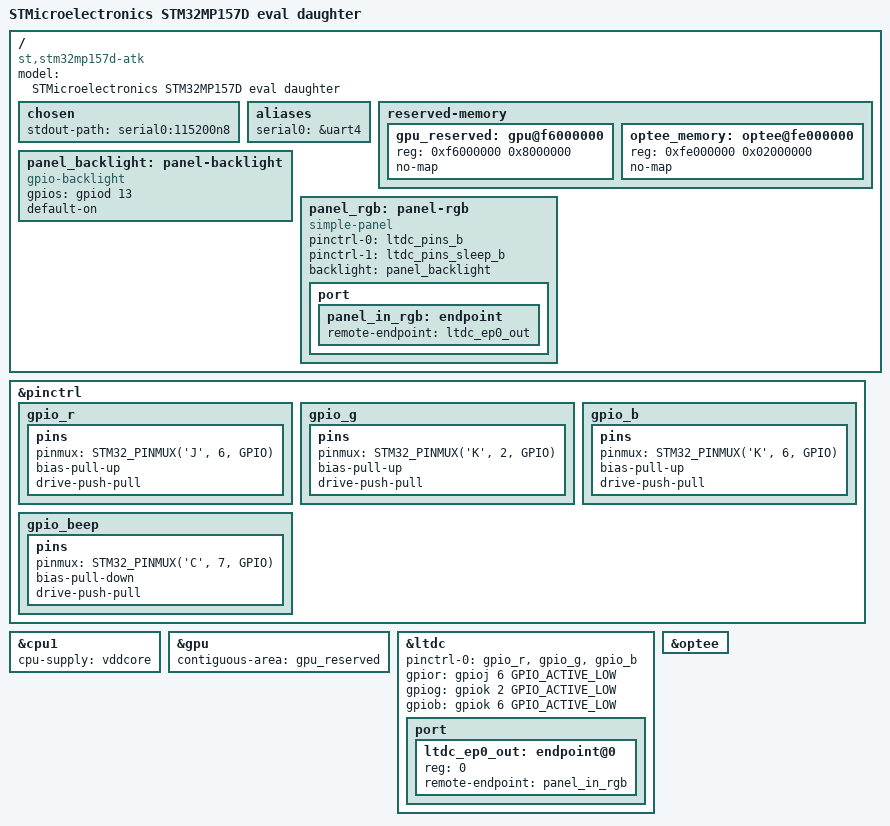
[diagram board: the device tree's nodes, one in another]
// SPDX-License-Identifier: (GPL-2.0+ OR BSD-3-Clause)
/*
 * Copyright (C) STMicroelectronics 2019 - All Rights Reserved
 * Author: Alexandre Torgue <alexandre.torgue@st.com> for STMicroelectronics.
 */
/dts-v1/;

#include "stm32mp157.dtsi"
#include "stm32mp15xd.dtsi"
#include "stm32mp15-pinctrl.dtsi"
#include "stm32mp15xxaa-pinctrl.dtsi"
#include "stm32mp157-m4-srm.dtsi"
#include "stm32mp157-m4-srm-pinctrl.dtsi"
#include "stm32mp157d-atk.dtsi"

/ {
	model = "STMicroelectronics STM32MP157D eval daughter";
	compatible = "st,stm32mp157d-atk", "st,stm32mp157";

	chosen {
		stdout-path = "serial0:115200n8";
	};

	aliases {
		serial0 = &uart4;
	};

	reserved-memory {
		gpu_reserved: gpu@f6000000 {
			reg = <0xf6000000 0x8000000>;
			no-map;
		};

		optee_memory: optee@fe000000 {
			reg = <0xfe000000 0x02000000>;
			no-map;
		};
	};

	panel_backlight: panel-backlight {
		compatible = "gpio-backlight";
		gpios = <&gpiod 13 GPIO_ACTIVE_HIGH>;
		default-on;
		status = "okay";
	};

    panel_rgb: panel-rgb {
        compatible = "simple-panel";
        pinctrl-names = "default", "sleep";
        pinctrl-0 = <&ltdc_pins_b>;
        pinctrl-1 = <&ltdc_pins_sleep_b>;
        backlight = <&panel_backlight>;
        status = "okay";

        port {
            panel_in_rgb: endpoint {
                remote-endpoint = <&ltdc_ep0_out>;
            };
        };
    };


};

&pinctrl {
   gpio_r:gpio_r {
        pins {
            pinmux = <STM32_PINMUX('J', 6, GPIO)>; /* PJ6.GPIO */
            bias-pull-up;
            drive-push-pull;
        };
    };
   gpio_g:gpio_g {
        pins {
            pinmux = <STM32_PINMUX('K', 2, GPIO)>; /* PK2.GPIO */
            bias-pull-up;
            drive-push-pull;
        };
    };
   gpio_b:gpio_b {
        pins {
            pinmux = <STM32_PINMUX('K', 6, GPIO)>; /* PK6.GPIO */
            bias-pull-up;
            drive-push-pull;
        };
    };
   gpio_beep:gpio_beep {
        pins {
            pinmux = <STM32_PINMUX('C', 7, GPIO)>; /* PK6.GPIO */
            bias-pull-down;
            drive-push-pull;
        };
    };
};

&cpu1{
	cpu-supply = <&vddcore>;
};

&gpu {
	contiguous-area = <&gpu_reserved>;
	status = "okay";
};

&ltdc {
	status = "okay";
    pinctrl-names = "default";
    pinctrl-0 = <&gpio_r>,<&gpio_g>, <&gpio_b>;
    gpior = <&gpioj 6 GPIO_ACTIVE_LOW>;
    gpiog = <&gpiok 2 GPIO_ACTIVE_LOW>;
    gpiob = <&gpiok 6 GPIO_ACTIVE_LOW>;

	port {
		#address-cells = <1>;
		#size-cells = <0>;

		ltdc_ep0_out: endpoint@0 {
			reg = <0>;
			remote-endpoint = <&panel_in_rgb>;
		};
	};
};


&optee {
	status = "okay";
};
